# MB9BF52xL register map
File version: 1.7
Registers are 8-bit, read-write, reset 0x0 unless marked. A register's access mark holds for its fields unless they carry their own. Offsets are from the block's base; [hi:lo] are bit positions; {n}, {i} and the like mark numbered series; 'fields as' and 'values as' point back to an identical list.

## WC — Watch Counter
Base 0x4003A000
0x00 WCRD ro — Watch Counter Read Register
  [5:0] CTR — counter value
0x01 WCRL — Watch Counter Reload Register
  [5:0] RLC — reload value
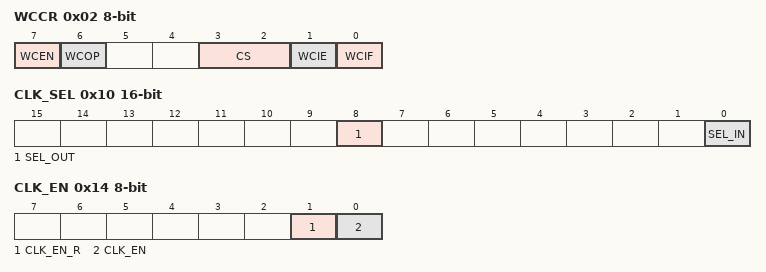
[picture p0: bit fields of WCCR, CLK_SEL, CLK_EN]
0x02 WCCR — Watch Counter Control Register
  [7] WCEN — Watch counter operation enable bit
  [6] WCOP ro — Watch counter operating state flag
  [3:2] CS — Count clock select bits
  [1] WCIE — Interrupt request enable bit
  [0] WCIF — Interrupt request flag bit
0x10 CLK_SEL 16-bit — Clock Selection Register
  [8] SEL_OUT — Output clock selection bit
  [0] SEL_IN — Input clock selection bit
0x14 CLK_EN — Division Clock Enable Register
  [1] CLK_EN_R — Division clock enable read bit
  [0] CLK_EN — Division clock enable bit

## MFT_PPG — PPG Configuration
Base 0x40024000
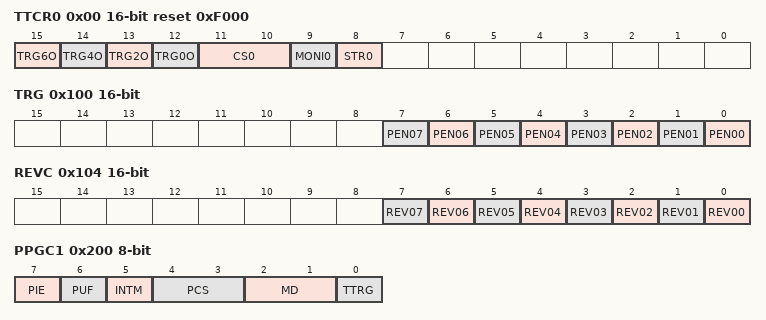
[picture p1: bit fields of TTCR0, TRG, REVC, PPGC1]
0x00 TTCR0 16-bit reset 0xF000 — PPG Start Trigger Control Register 0
  [15] TRG6O — PPG6 trigger stop bit
  [14] TRG4O — PPG4 trigger stop bit
  [13] TRG2O — PPG2 trigger stop bit
  [12] TRG0O — PPG0 trigger stop bit
  [11:10] CS0 — 8-bit UP counter clock select bits for comparison
  [9] MONI0 ro — 8-bit UP counter operation state monitor bit for comparison
  [8] STR0 — 8-bit UP counter operation enable bit for comparison
0x08 COMP0 16-bit (reset mask 0xFF00) — PPG Compare Register 0
0x0C COMP2 — PPG Compare Register 2
0x10 COMP4 16-bit (reset mask 0xFF00) — PPG Compare Register 4
0x14 COMP6 — PPG Compare Register 6
0x100 TRG 16-bit — PPG Start Register 0
  [n] PEN{n:02} (n=0..7) — PPG{n} Start Trigger bit
0x104 REVC 16-bit — Output Reverse Register 0
  [n] REV{n:02} (n=0..7) — PPG{n} Output Reverse Enable bit
0x200 PPGC1 — PPG Operation Mode Control Register 1
  [7] PIE — PPG Interrupt Enable bit
  [6] PUF — PPG Counter Underflow bit
  [5] INTM — Interrupt Mode Select bit
  [4:3] PCS — PPG DOWN Counter Operation Clock Select bits
  [2:1] MD — PPG Operation Mode Set bits
  [0] TTRG — PPG start trigger select bit
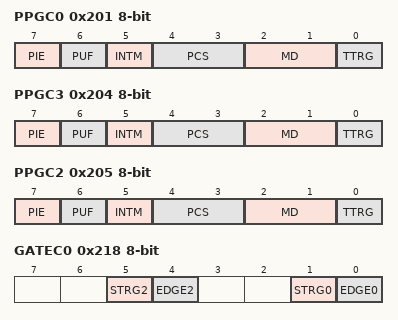
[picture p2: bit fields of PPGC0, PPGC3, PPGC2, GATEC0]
0x201 PPGC0 — PPG Operation Mode Control Register 0
  fields as PPGC1
0x204 PPGC3 — PPG Operation Mode Control Register 3
  fields as PPGC1
0x205 PPGC2 — PPG Operation Mode Control Register 2
  fields as PPGC1
{0x208+4i} PRLL{i} reset not defined (i=0..3) — PPG{i} Reload Registers Low
  [7:0] PRLL — Reload Registers Low
{0x209+4i} PRLH{i} reset not defined (i=0..3) — PPG{i} Reload Registers High
  [7:0] PRLH — Reload Registers High
0x218 GATEC0 — PPG Gate Function Control Registers 0
  [5] STRG2 — Select a trigger for PPG2
  [4] EDGE2 — Select Start Effective Level for PPG2
  [1] STRG0 — Select a trigger for PPG0
  [0] EDGE0 — Select Start Effective Level for PPG0
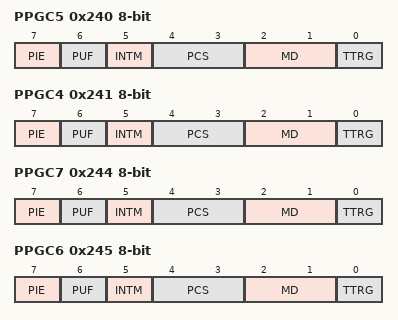
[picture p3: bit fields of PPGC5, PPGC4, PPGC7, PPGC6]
0x240 PPGC5 — PPG Operation Mode Control Register 5
  fields as PPGC1
0x241 PPGC4 — PPG Operation Mode Control Register 4
  fields as PPGC1
0x244 PPGC7 — PPG Operation Mode Control Register 7
  fields as PPGC1
0x245 PPGC6 — PPG Operation Mode Control Register 6
  fields as PPGC1
{0x238+4i} PRLL{i} reset not defined (i=4..7) — PPG{i} Reload Registers Low
  [7:0] PRLL — Reload Registers Low
{0x239+4i} PRLH{i} reset not defined (i=4..7) — PPG{i} Reload Registers High
  [7:0] PRLH — Reload Registers High
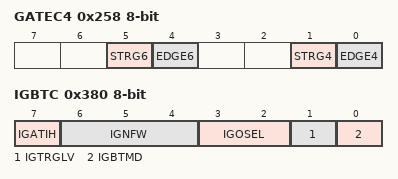
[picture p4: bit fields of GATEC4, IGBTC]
0x258 GATEC4 — PPG Gate Function Control Registers 4
  [5] STRG6 — Select a trigger for PPG6
  [4] EDGE6 — Select Start Effective Level for PPG6
  [1] STRG4 — Select a trigger for PPG4
  [0] EDGE4 — Select Start Effective Level for PPG4
0x380 IGBTC — IGBT Mode Control Register
  [7] IGATIH — Stop prohibition mode selection in output active bit
  [6:4] IGNFW — Noise filter width selection bit
  [3:2] IGOSEL — Output level selection bit
  [1] IGTRGLV — Trigger input level selection bit
  [0] IGBTMD — IGBT mode selection bit

## EXTI — External Interrupt and NMI Control
Base 0x40030000
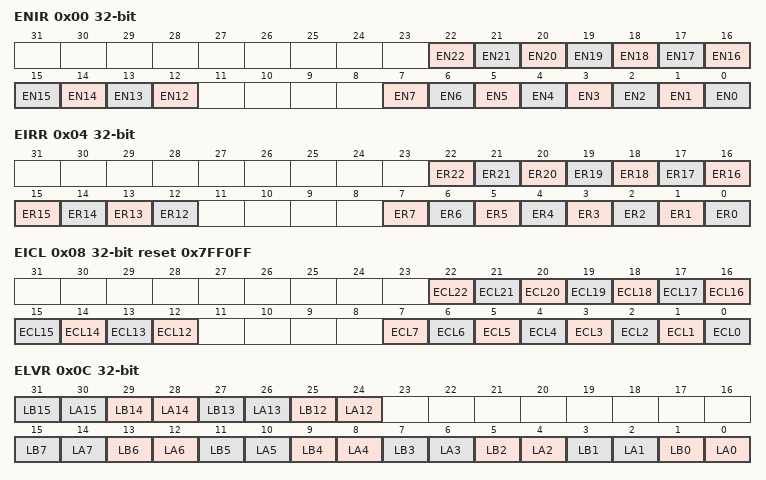
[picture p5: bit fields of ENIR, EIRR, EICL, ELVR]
0x00 ENIR 32-bit — Enable Interrupt Request Register
  [n] EN{n} (n=12..22) — Bit{n} of ENIR
  [n] EN{n} (n=0..7) — Bit{n} of ENIR
0x04 EIRR 32-bit ro reset not defined — External Interrupt Request Register
  [n] ER{n} rw (n=16..22) — Bit{n} of EIRR
  [n] ER{n} (n=12..15) — Bit{n} of EIRR
  [n] ER{n} (n=0..7) — Bit{n} of EIRR
0x08 EICL 32-bit reset 0x7FF0FF — External Interrupt Clear Register
  [n] ECL{n} (n=12..22) — Bit{n} of EICL
  [n] ECL{n} (n=0..7) — Bit{n} of EICL
0x0C ELVR 32-bit — External Interrupt Level Register
  [2n+1] LB{n} (n=12..15) — Bit{2n+1} of ELVR
  [2n] LA{n} (n=12..15) — Bit{2n} of ELVR
  [2n+1] LB{n} (n=0..7) — Bit{2n+1} of ELVR
  [2n] LA{n} (n=0..7) — Bit{2n} of ELVR
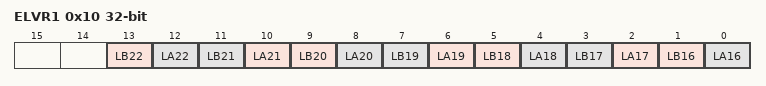
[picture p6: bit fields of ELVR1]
0x10 ELVR1 32-bit — External Interrupt Level Register 1
  [2n-31] LB{n} (n=16..22) — Bit{2n-31} of ELVR1
  [2n-32] LA{n} (n=16..22) — Bit{2n-32} of ELVR1
0x14 NMIRR ro — Non Maskable Interrupt Request Register
  [0] NR — NMI interrupt request detection bit
0x18 NMICL reset 0x1 — Non Maskable Interrupt Clear Register
  [0] NCL — NMI interrupt cause clear bit
